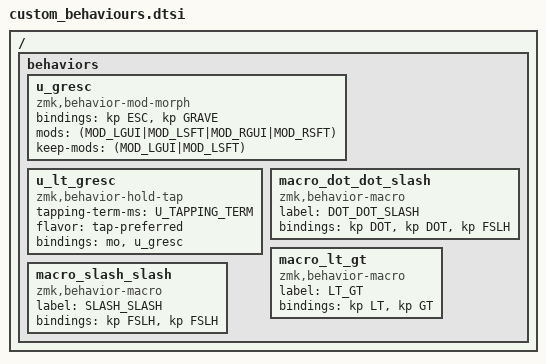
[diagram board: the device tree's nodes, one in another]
#define U_TAPPING_TERM 200

/ {
    behaviors {
      u_gresc: u_gresc {
        compatible = "zmk,behavior-mod-morph";
        #binding-cells = <0>;
        bindings = <&kp ESC>, <&kp GRAVE>;
        mods = <(MOD_LGUI|MOD_LSFT|MOD_RGUI|MOD_RSFT)>;
        keep-mods = <(MOD_LGUI|MOD_LSFT)>;
      };
      u_lt_gresc: u_lt_gresc {
        compatible = "zmk,behavior-hold-tap";
        #binding-cells = <2>;
        tapping-term-ms = <U_TAPPING_TERM>;
        flavor = "tap-preferred";
        bindings = <&mo>, <&u_gresc>;
      };
      // Macro for "../" (three characters: ., ., /)
      macro_dot_dot_slash: macro_dot_dot_slash {
          label = "DOT_DOT_SLASH";
          compatible = "zmk,behavior-macro";
          #binding-cells = <0>;
          // Each &kp ... sends one character
          bindings = <
              &kp DOT
              &kp DOT
              &kp FSLH
          >;
      };
      // Macro for "<>" (two characters: <, >)
      macro_lt_gt: macro_lt_gt {
          label = "LT_GT";
          compatible = "zmk,behavior-macro";
          #binding-cells = <0>;
          bindings = <
              &kp LT
              &kp GT
          >;
      };

      // Macro for "//" (two characters: /, /)
      macro_slash_slash: macro_slash_slash {
          label = "SLASH_SLASH";
          compatible = "zmk,behavior-macro";
          #binding-cells = <0>;
          bindings = <
              &kp FSLH
              &kp FSLH
          >;
      };

      // macro_ctrl_tab: macro_ctrl_tab {
      //     label = "CTRL_TAB";
      //     compatible = "zmk,behavior-macro";
      //     #binding-cells = <0>;
      //     // The bindings below send a Ctrl press, then Tab, then release Ctrl.
      //     // Depending on your needs, you might need to adjust the timing.
      //     bindings = <
      //         &kp LCTL  // Sends Left Control down
      //         &kp TAB   // Sends Tab
      //         // The behavior automatically releases keys unless configured otherwise.
      //     >;
      //     // Use a release-mode that holds the keys until the macro finishes
      //     release-mode = "hold-then-release";
      // };

      // macro_ctrl_shift_tab: macro_ctrl_shift_tab {
      //     label = "CTRL_TAB";
      //     compatible = "zmk,behavior-macro";
      //     #binding-cells = <0>;
      //     // The bindings below send a Ctrl press, then Tab, then release Ctrl.
      //     // Depending on your needs, you might need to adjust the timing.
      //     bindings = <
      //         &kp LCTL  // Sends Left Control down
      //         &kp LSFT  // Sends Left Control down
      //         &kp TAB   // Sends Tab
      //         // The behavior automatically releases keys unless configured otherwise.
      //     >;
      //     // Use a release-mode that holds the keys until the macro finishes
      //     release-mode = "hold-then-release";
      // };
    };
  };
  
